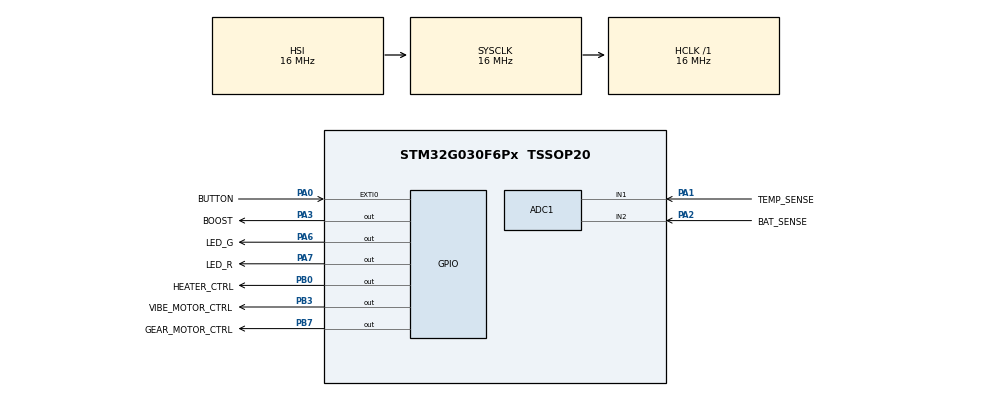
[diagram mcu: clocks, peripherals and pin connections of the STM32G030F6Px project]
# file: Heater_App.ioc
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ADC1.Channel-2\#ChannelRegularConversion=ADC_CHANNEL_1
ADC1.Channel-3\#ChannelRegularConversion=ADC_CHANNEL_2
ADC1.ContinuousConvMode=DISABLE
ADC1.DiscontinuousConvMode=ENABLE
ADC1.NbrOfConversion=2
ADC1.NbrOfConversionFlag=1
ADC1.Rank-2\#ChannelRegularConversion=1
ADC1.Rank-3\#ChannelRegularConversion=2
ADC1.SamplingTime-2\#ChannelRegularConversion=ADC_SAMPLINGTIME_COMMON_1
ADC1.SamplingTime-3\#ChannelRegularConversion=ADC_SAMPLINGTIME_COMMON_1
ADC1.SelectedChannel=ADC_CHANNEL_1|ADC_CHANNEL_2
ADC1.master=1
Mcu.Family=STM32G0
Mcu.Name=STM32G030F6Px
Mcu.Package=TSSOP20
NVIC.EXTI0_1_IRQn=true\:0\:0\:false\:false\:true\:true\:true\:true
PA0.GPIO_Label=BUTTON
PA0.GPIO_ModeDefaultEXTI=GPIO_MODE_IT_FALLING
PA0.Signal=GPXTI0
PA1.GPIO_Label=TEMP_SENSE
PA1.Mode=IN1
PA1.Signal=ADC1_IN1
PA13.Mode=Serial_Wire
PA13.Signal=SYS_SWDIO
PA14-BOOT0.Mode=Serial_Wire
PA14-BOOT0.Signal=SYS_SWCLK
PA14-BOOT0__PA15.StandardMode=true
PA2.GPIO_Label=BAT_SENSE
PA2.Mode=IN2
PA2.Signal=ADC1_IN2
PA3.GPIO_Label=BOOST
PA3.PinState=GPIO_PIN_RESET
PA3.Signal=GPIO_Output
PA6.GPIO_Label=LED_G
PA6.Signal=GPIO_Output
PA7.GPIO_Label=LED_R
PA7.Signal=GPIO_Output
PB0.GPIO_Label=HEATER_CTRL
PB0.Signal=GPIO_Output
PB0__PB1__PB2__PA8.StandardMode=true
PB3.GPIO_Label=VIBE_MOTOR_CTRL
PB3.PinState=GPIO_PIN_SET
PB3.Signal=GPIO_Output
PB3__PB4__PB5__PB6.StandardMode=true
PB7.GPIO_Label=GEAR_MOTOR_CTRL
PB7.Signal=GPIO_Output
PB7__PB8.StandardMode=true
PC14-OSC32_IN\ (PC14)__PB9.StandardMode=true
ProjectManager.HeapSize=0x200
ProjectManager.StackSize=0x400
ProjectManager.TargetToolchain=STM32CubeIDE
RCC.AHBFreq_Value=16000000
RCC.CortexFreq_Value=16000000
RCC.EXTERNAL_CLOCK_VALUE=12288000
RCC.HCLKFreq_Value=16000000
RCC.HSE_VALUE=8000000
RCC.HSI_VALUE=16000000
RCC.LSE_VALUE=32768
RCC.SYSCLKFreq_VALUE=16000000
RCC.VCOOutputFreq_Value=128000000
board=custom

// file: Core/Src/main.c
/* USER CODE BEGIN Header */
/**
  ******************************************************************************
  * @file           : main.c
  * @brief          : Main program body
  ******************************************************************************
  * @attention
  *
  * Copyright (c) 2024 STMicroelectronics.
  * All rights reserved.
  *
  * This software is licensed under terms that can be found in the LICENSE file
  * in the root directory of this software component.
  * If no LICENSE file comes with this software, it is provided AS-IS.
  *
  ******************************************************************************
  */
/* USER CODE END Header */
#include "main.h"
#include "adc.h"
#include "gpio.h"
#include "app.h"

void SystemClock_Config(void);

int main(void)
{

  /* MCU Configuration--------------------------------------------------------*/

  /* Reset of all peripherals, Initializes the Flash interface and the Systick. */
  HAL_Init();

  /* Configure the system clock */
  SystemClock_Config();

  /* Initialize all configured peripherals */
  MX_GPIO_Init();
  MX_ADC1_Init();
  /* USER CODE BEGIN 2 */
  App_setup();
  /* USER CODE END 2 */

  /* Infinite loop */
  /* USER CODE BEGIN WHILE */
  while (1)
  {
	  App_loop();
    /* USER CODE END WHILE */

  }
}

void SystemClock_Config(void)
{
  RCC_OscInitTypeDef RCC_OscInitStruct = {0};
  RCC_ClkInitTypeDef RCC_ClkInitStruct = {0};

  /** Configure the main internal regulator output voltage
  */
  HAL_PWREx_ControlVoltageScaling(PWR_REGULATOR_VOLTAGE_SCALE1);

  /** Initializes the RCC Oscillators according to the specified parameters
  * in the RCC_OscInitTypeDef structure.
  */
  RCC_OscInitStruct.OscillatorType = RCC_OSCILLATORTYPE_HSI;
  RCC_OscInitStruct.HSIState = RCC_HSI_ON;
  RCC_OscInitStruct.HSIDiv = RCC_HSI_DIV1;
  RCC_OscInitStruct.HSICalibrationValue = RCC_HSICALIBRATION_DEFAULT;
  RCC_OscInitStruct.PLL.PLLState = RCC_PLL_NONE;
  if (HAL_RCC_OscConfig(&RCC_OscInitStruct) != HAL_OK)
  {
    Error_Handler();
  }

  /** Initializes the CPU, AHB and APB buses clocks
  */
  RCC_ClkInitStruct.ClockType = RCC_CLOCKTYPE_HCLK|RCC_CLOCKTYPE_SYSCLK
                              |RCC_CLOCKTYPE_PCLK1;
  RCC_ClkInitStruct.SYSCLKSource = RCC_SYSCLKSOURCE_HSI;
  RCC_ClkInitStruct.AHBCLKDivider = RCC_SYSCLK_DIV1;
  RCC_ClkInitStruct.APB1CLKDivider = RCC_HCLK_DIV1;

  if (HAL_RCC_ClockConfig(&RCC_ClkInitStruct, FLASH_LATENCY_0) != HAL_OK)
  {
    Error_Handler();
  }
}

void Error_Handler(void)
{
  __disable_irq();
  while (1)
  {
  }
}
